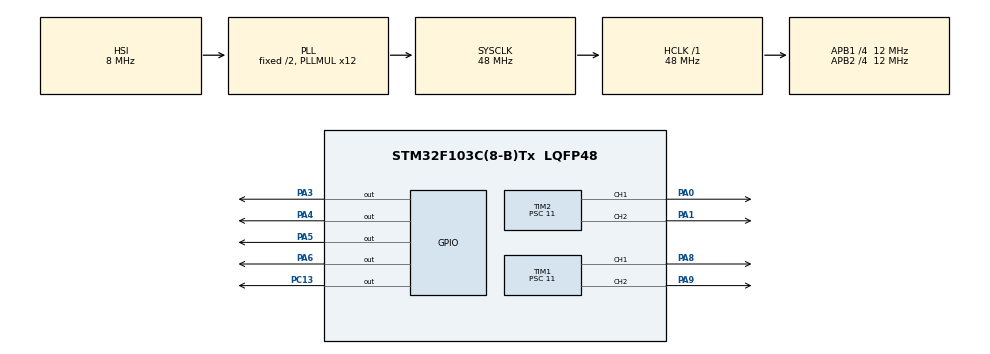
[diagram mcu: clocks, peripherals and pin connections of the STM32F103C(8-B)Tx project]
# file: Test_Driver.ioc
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Mcu.Family=STM32F1
Mcu.Name=STM32F103C(8-B)Tx
Mcu.Package=LQFP48
NVIC.PriorityGroup=NVIC_PRIORITYGROUP_4
PA0-WKUP.Signal=S_TIM2_CH1_ETR
PA1.Signal=S_TIM2_CH2
PA13.Mode=Serial_Wire
PA13.Signal=SYS_JTMS-SWDIO
PA14.Mode=Serial_Wire
PA14.Signal=SYS_JTCK-SWCLK
PA3.PinState=GPIO_PIN_RESET
PA3.Signal=GPIO_Output
PA4.PinState=GPIO_PIN_RESET
PA4.Signal=GPIO_Output
PA5.Signal=GPIO_Output
PA6.Signal=GPIO_Output
PA8.Signal=S_TIM1_CH1
PA9.Signal=S_TIM1_CH2
PC13-TAMPER-RTC.GPIO_PuPd=GPIO_PULLUP
PC13-TAMPER-RTC.PinState=GPIO_PIN_RESET
PC13-TAMPER-RTC.Signal=GPIO_Output
ProjectManager.HeapSize=0x200
ProjectManager.StackSize=0x400
ProjectManager.TargetToolchain=MDK-ARM V5.32
RCC.AHBFreq_Value=48000000
RCC.APB1CLKDivider=RCC_HCLK_DIV4
RCC.APB1Freq_Value=12000000
RCC.APB1TimFreq_Value=24000000
RCC.APB2CLKDivider=RCC_HCLK_DIV4
RCC.APB2Freq_Value=12000000
RCC.APB2TimFreq_Value=24000000
RCC.HCLKFreq_Value=48000000
RCC.PLLMUL=RCC_PLL_MUL12
RCC.SYSCLKFreq_VALUE=48000000
RCC.SYSCLKSource=RCC_SYSCLKSOURCE_PLLCLK
RCC.USBFreq_Value=48000000
SH.S_TIM1_CH1.0=TIM1_CH1,PWM Generation1 CH1
SH.S_TIM1_CH2.0=TIM1_CH2,PWM Generation2 CH2
SH.S_TIM2_CH1_ETR.0=TIM2_CH1,PWM Generation1 CH1
SH.S_TIM2_CH2.0=TIM2_CH2,PWM Generation2 CH2
TIM1.Channel-PWM\ Generation1\ CH1=TIM_CHANNEL_1
TIM1.Channel-PWM\ Generation2\ CH2=TIM_CHANNEL_2
TIM1.Period=100
TIM1.Prescaler=11
TIM2.Channel-PWM\ Generation1\ CH1=TIM_CHANNEL_1
TIM2.Channel-PWM\ Generation2\ CH2=TIM_CHANNEL_2
TIM2.Period=100
TIM2.Prescaler=11
board=custom

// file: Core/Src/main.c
/* USER CODE BEGIN Header */
/**
  ******************************************************************************
  * @file           : main.c
  * @brief          : Main program body
  ******************************************************************************
  * @attention
  *
  * Copyright (c) 2023 STMicroelectronics.
  * All rights reserved.
  *
  * This software is licensed under terms that can be found in the LICENSE file
  * in the root directory of this software component.
  * If no LICENSE file comes with this software, it is provided AS-IS.
  *
  ******************************************************************************
  */
/* USER CODE END Header */
#include "main.h"

TIM_HandleTypeDef htim1;
TIM_HandleTypeDef htim2;

/* USER CODE BEGIN PV */
uint16_t pwm1;
uint16_t pwm2;
uint16_t dir1;
uint16_t dir2;
/* USER CODE END PV */

void SystemClock_Config(void);
static void MX_GPIO_Init(void);
static void MX_TIM1_Init(void);
static void MX_TIM2_Init(void);

int main(void)
{

  /* MCU Configuration--------------------------------------------------------*/

  /* Reset of all peripherals, Initializes the Flash interface and the Systick. */
  HAL_Init();

  /* Configure the system clock */
  SystemClock_Config();

  /* Initialize all configured peripherals */
  MX_GPIO_Init();
  MX_TIM1_Init();
  MX_TIM2_Init();
  /* USER CODE BEGIN 2 */
	HAL_TIM_PWM_Start(&htim1, TIM_CHANNEL_1);	// khoi tao timer 1
	HAL_TIM_PWM_Start(&htim2, TIM_CHANNEL_1);	// khoi tao timer 2
	HAL_TIM_PWM_Start(&htim1, TIM_CHANNEL_2);	// khoi tao timer 1
	HAL_TIM_PWM_Start(&htim2, TIM_CHANNEL_2);	// khoi tao timer 2
  /* USER CODE END 2 */

  /* Infinite loop */
  while (1)
  {
		HAL_GPIO_WritePin(GPIOA, GPIO_PIN_3, 1);
		HAL_GPIO_WritePin(GPIOA, GPIO_PIN_4, 1);
		HAL_GPIO_WritePin(GPIOA, GPIO_PIN_5, 1);
		HAL_GPIO_WritePin(GPIOA, GPIO_PIN_6, 1);

		__HAL_TIM_SetCompare(&htim1, TIM_CHANNEL_1, pwm1);
		__HAL_TIM_SetCompare(&htim1, TIM_CHANNEL_2, pwm2);
		__HAL_TIM_SetCompare(&htim2, TIM_CHANNEL_1, pwm1);
		__HAL_TIM_SetCompare(&htim2, TIM_CHANNEL_2, pwm2);
  }
}

void SystemClock_Config(void)
{
  RCC_OscInitTypeDef RCC_OscInitStruct = {0};
  RCC_ClkInitTypeDef RCC_ClkInitStruct = {0};

  /** Initializes the RCC Oscillators according to the specified parameters
  * in the RCC_OscInitTypeDef structure.
  */
  RCC_OscInitStruct.OscillatorType = RCC_OSCILLATORTYPE_HSI;
  RCC_OscInitStruct.HSIState = RCC_HSI_ON;
  RCC_OscInitStruct.HSICalibrationValue = RCC_HSICALIBRATION_DEFAULT;
  RCC_OscInitStruct.PLL.PLLState = RCC_PLL_ON;
  RCC_OscInitStruct.PLL.PLLSource = RCC_PLLSOURCE_HSI_DIV2;
  RCC_OscInitStruct.PLL.PLLMUL = RCC_PLL_MUL12;
  if (HAL_RCC_OscConfig(&RCC_OscInitStruct) != HAL_OK)
  {
    Error_Handler();
  }

  /** Initializes the CPU, AHB and APB buses clocks
  */
  RCC_ClkInitStruct.ClockType = RCC_CLOCKTYPE_HCLK|RCC_CLOCKTYPE_SYSCLK
                              |RCC_CLOCKTYPE_PCLK1|RCC_CLOCKTYPE_PCLK2;
  RCC_ClkInitStruct.SYSCLKSource = RCC_SYSCLKSOURCE_PLLCLK;
  RCC_ClkInitStruct.AHBCLKDivider = RCC_SYSCLK_DIV1;
  RCC_ClkInitStruct.APB1CLKDivider = RCC_HCLK_DIV4;
  RCC_ClkInitStruct.APB2CLKDivider = RCC_HCLK_DIV4;

  if (HAL_RCC_ClockConfig(&RCC_ClkInitStruct, FLASH_LATENCY_1) != HAL_OK)
  {
    Error_Handler();
  }
}

static void MX_TIM1_Init(void)
{

  TIM_MasterConfigTypeDef sMasterConfig = {0};
  TIM_OC_InitTypeDef sConfigOC = {0};
  TIM_BreakDeadTimeConfigTypeDef sBreakDeadTimeConfig = {0};

  htim1.Instance = TIM1;
  htim1.Init.Prescaler = 11;
  htim1.Init.CounterMode = TIM_COUNTERMODE_UP;
  htim1.Init.Period = 100;
  htim1.Init.ClockDivision = TIM_CLOCKDIVISION_DIV1;
  htim1.Init.RepetitionCounter = 0;
  htim1.Init.AutoReloadPreload = TIM_AUTORELOAD_PRELOAD_DISABLE;
  if (HAL_TIM_PWM_Init(&htim1) != HAL_OK)
  {
    Error_Handler();
  }
  sMasterConfig.MasterOutputTrigger = TIM_TRGO_RESET;
  sMasterConfig.MasterSlaveMode = TIM_MASTERSLAVEMODE_DISABLE;
  if (HAL_TIMEx_MasterConfigSynchronization(&htim1, &sMasterConfig) != HAL_OK)
  {
    Error_Handler();
  }
  sConfigOC.OCMode = TIM_OCMODE_PWM1;
  sConfigOC.Pulse = 0;
  sConfigOC.OCPolarity = TIM_OCPOLARITY_HIGH;
  sConfigOC.OCNPolarity = TIM_OCNPOLARITY_HIGH;
  sConfigOC.OCFastMode = TIM_OCFAST_DISABLE;
  sConfigOC.OCIdleState = TIM_OCIDLESTATE_RESET;
  sConfigOC.OCNIdleState = TIM_OCNIDLESTATE_RESET;
  if (HAL_TIM_PWM_ConfigChannel(&htim1, &sConfigOC, TIM_CHANNEL_1) != HAL_OK)
  {
    Error_Handler();
  }
  if (HAL_TIM_PWM_ConfigChannel(&htim1, &sConfigOC, TIM_CHANNEL_2) != HAL_OK)
  {
    Error_Handler();
  }
  sBreakDeadTimeConfig.OffStateRunMode = TIM_OSSR_DISABLE;
  sBreakDeadTimeConfig.OffStateIDLEMode = TIM_OSSI_DISABLE;
  sBreakDeadTimeConfig.LockLevel = TIM_LOCKLEVEL_OFF;
  sBreakDeadTimeConfig.DeadTime = 0;
  sBreakDeadTimeConfig.BreakState = TIM_BREAK_DISABLE;
  sBreakDeadTimeConfig.BreakPolarity = TIM_BREAKPOLARITY_HIGH;
  sBreakDeadTimeConfig.AutomaticOutput = TIM_AUTOMATICOUTPUT_DISABLE;
  if (HAL_TIMEx_ConfigBreakDeadTime(&htim1, &sBreakDeadTimeConfig) != HAL_OK)
  {
    Error_Handler();
  }
  HAL_TIM_MspPostInit(&htim1);

}

static void MX_TIM2_Init(void)
{

  TIM_MasterConfigTypeDef sMasterConfig = {0};
  TIM_OC_InitTypeDef sConfigOC = {0};

  htim2.Instance = TIM2;
  htim2.Init.Prescaler = 11;
  htim2.Init.CounterMode = TIM_COUNTERMODE_UP;
  htim2.Init.Period = 100;
  htim2.Init.ClockDivision = TIM_CLOCKDIVISION_DIV1;
  htim2.Init.AutoReloadPreload = TIM_AUTORELOAD_PRELOAD_DISABLE;
  if (HAL_TIM_PWM_Init(&htim2) != HAL_OK)
  {
    Error_Handler();
  }
  sMasterConfig.MasterOutputTrigger = TIM_TRGO_RESET;
  sMasterConfig.MasterSlaveMode = TIM_MASTERSLAVEMODE_DISABLE;
  if (HAL_TIMEx_MasterConfigSynchronization(&htim2, &sMasterConfig) != HAL_OK)
  {
    Error_Handler();
  }
  sConfigOC.OCMode = TIM_OCMODE_PWM1;
  sConfigOC.Pulse = 0;
  sConfigOC.OCPolarity = TIM_OCPOLARITY_HIGH;
  sConfigOC.OCFastMode = TIM_OCFAST_DISABLE;
  if (HAL_TIM_PWM_ConfigChannel(&htim2, &sConfigOC, TIM_CHANNEL_1) != HAL_OK)
  {
    Error_Handler();
  }
  if (HAL_TIM_PWM_ConfigChannel(&htim2, &sConfigOC, TIM_CHANNEL_2) != HAL_OK)
  {
    Error_Handler();
  }
  HAL_TIM_MspPostInit(&htim2);

}

static void MX_GPIO_Init(void)
{
  GPIO_InitTypeDef GPIO_InitStruct = {0};

  /* GPIO Ports Clock Enable */
  __HAL_RCC_GPIOC_CLK_ENABLE();
  __HAL_RCC_GPIOD_CLK_ENABLE();
  __HAL_RCC_GPIOA_CLK_ENABLE();
  __HAL_RCC_GPIOB_CLK_ENABLE();

  /*Configure GPIO pin Output Level */
  HAL_GPIO_WritePin(GPIOC, GPIO_PIN_13, GPIO_PIN_RESET);

  /*Configure GPIO pin Output Level */
  HAL_GPIO_WritePin(GPIOA, GPIO_PIN_3|GPIO_PIN_4|GPIO_PIN_5|GPIO_PIN_6, GPIO_PIN_RESET);

  /*Configure GPIO pin : PC13 */
  GPIO_InitStruct.Pin = GPIO_PIN_13;
  GPIO_InitStruct.Mode = GPIO_MODE_OUTPUT_PP;
  GPIO_InitStruct.Pull = GPIO_PULLUP;
  GPIO_InitStruct.Speed = GPIO_SPEED_FREQ_LOW;
  HAL_GPIO_Init(GPIOC, &GPIO_InitStruct);

  /*Configure GPIO pins : PC14 PC15 */
  GPIO_InitStruct.Pin = GPIO_PIN_14|GPIO_PIN_15;
  GPIO_InitStruct.Mode = GPIO_MODE_ANALOG;
  HAL_GPIO_Init(GPIOC, &GPIO_InitStruct);

  /*Configure GPIO pins : PD0 PD1 */
  GPIO_InitStruct.Pin = GPIO_PIN_0|GPIO_PIN_1;
  GPIO_InitStruct.Mode = GPIO_MODE_ANALOG;
  HAL_GPIO_Init(GPIOD, &GPIO_InitStruct);

  /*Configure GPIO pins : PA2 PA7 PA10 PA11
                           PA12 PA15 */
  GPIO_InitStruct.Pin = GPIO_PIN_2|GPIO_PIN_7|GPIO_PIN_10|GPIO_PIN_11
                          |GPIO_PIN_12|GPIO_PIN_15;
  GPIO_InitStruct.Mode = GPIO_MODE_ANALOG;
  HAL_GPIO_Init(GPIOA, &GPIO_InitStruct);

  /*Configure GPIO pins : PA3 PA4 PA5 PA6 */
  GPIO_InitStruct.Pin = GPIO_PIN_3|GPIO_PIN_4|GPIO_PIN_5|GPIO_PIN_6;
  GPIO_InitStruct.Mode = GPIO_MODE_OUTPUT_PP;
  GPIO_InitStruct.Pull = GPIO_NOPULL;
  GPIO_InitStruct.Speed = GPIO_SPEED_FREQ_LOW;
  HAL_GPIO_Init(GPIOA, &GPIO_InitStruct);

  /*Configure GPIO pins : PB0 PB1 PB2 PB10
                           PB11 PB12 PB13 PB14
                           PB15 PB3 PB4 PB5
                           PB6 PB7 PB8 PB9 */
  GPIO_InitStruct.Pin = GPIO_PIN_0|GPIO_PIN_1|GPIO_PIN_2|GPIO_PIN_10
                          |GPIO_PIN_11|GPIO_PIN_12|GPIO_PIN_13|GPIO_PIN_14
                          |GPIO_PIN_15|GPIO_PIN_3|GPIO_PIN_4|GPIO_PIN_5
                          |GPIO_PIN_6|GPIO_PIN_7|GPIO_PIN_8|GPIO_PIN_9;
  GPIO_InitStruct.Mode = GPIO_MODE_ANALOG;
  HAL_GPIO_Init(GPIOB, &GPIO_InitStruct);

  /*Configure peripheral I/O remapping */
  __HAL_AFIO_REMAP_PD01_ENABLE();

}

void Error_Handler(void)
{
  __disable_irq();
  while (1)
  {
  }
}
